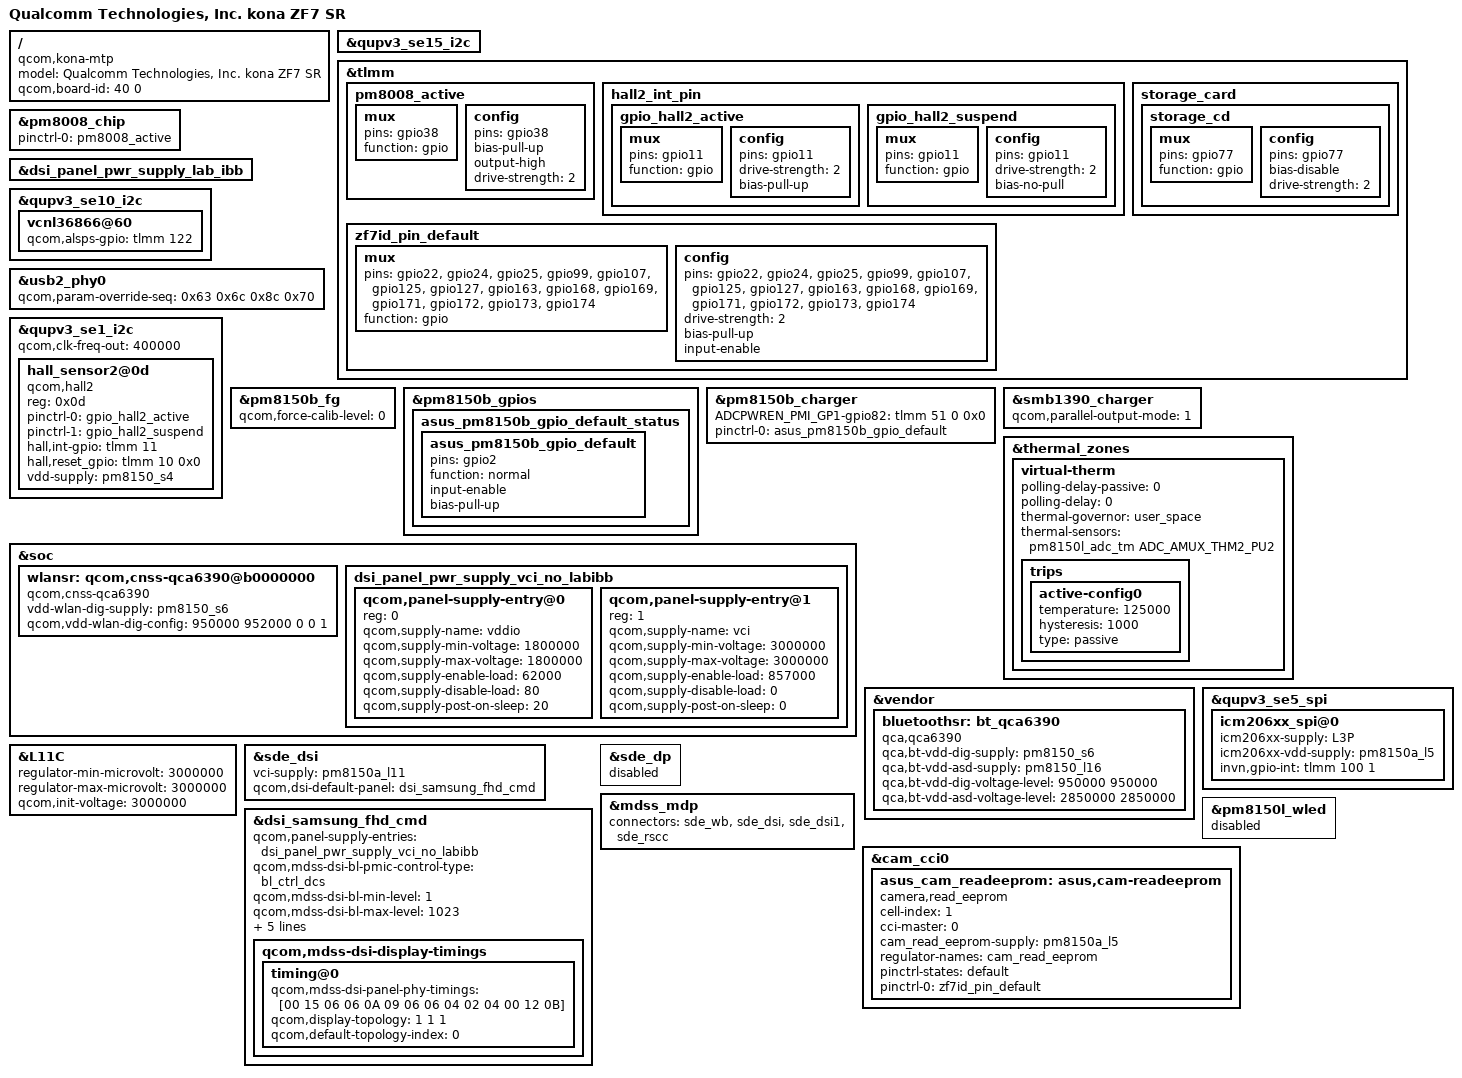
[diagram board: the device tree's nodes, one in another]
/dts-v1/;
/plugin/;

#include "zs670ks-evb-asus-overlay.dts"

#include "dsi-panel-samsung-fhd-cmd.dtsi"
#include "zs670ks-goodix-fp.dtsi"

/* ASUS BSP Clay: PM8008 regulator setting +++ */

&qupv3_se15_i2c {
        status = "ok";
        #include "pm8008.dtsi"
};

&tlmm {
        pm8008_active: pm8008_active {
                mux {
                        pins = "gpio38";
                        function = "gpio";
                };

                config {
                        pins = "gpio38";
                        bias-pull-up;
                        output-high;
                        drive-strength = <2>;
                };
        };
};

&pm8008_chip {
        pinctrl-names = "default";
        pinctrl-0 = <&pm8008_active>;
};


#include "camera/zs670ks-sr-camera-sensor-mtp.dtsi"

/ {
	model = "Qualcomm Technologies, Inc. kona ZF7 SR";
	compatible = "qcom,kona-mtp", "qcom,kona", "qcom,mtp";
	qcom,board-id = <40 0>;
};



/*    ====================================
 *    overlay for kona-v2.dtsi - start
 *    ====================================
 */

/*    ====================================
 *    overlay for kona-v2.dtsi - end
 *    ====================================
 */



/*    ====================================
 *    overlay for kona.dtsi - start
 *    ====================================
 */
&dsi_panel_pwr_supply_lab_ibb{
	/delete-node/ qcom,panel-supply-entry@1;
	/delete-node/ qcom,panel-supply-entry@2; 

};

&qupv3_se10_i2c {
        vcnl36866@60 {
			qcom,alsps-gpio = <&tlmm 122 0x0>;
		};
};

&usb2_phy0 {
	qcom,param-override-seq = < 0x63 0x6c
	                            0x8c 0x70>;
};

//ZS670KS_HALL_sensor_Timo_Xu ++++++++++
&qupv3_se1_i2c {
	status = "ok";
	qcom,clk-freq-out = <400000>;
	hall_sensor2@0d {
		compatible = "qcom,hall2";
		reg=<0x0d>;
		pinctrl-names = "hall2_gpio_high","hall2_gpio_low";
		pinctrl-0 = <&gpio_hall2_active>;
		pinctrl-1 = <&gpio_hall2_suspend>;			
		hall,int-gpio = <&tlmm 11 0x0>;
		hall,reset_gpio= <&tlmm 10 0x0>;
		vdd-supply = <&pm8150_s4>;
	};
};
//ZS670KS_HALL_sensor_Timo_Xu --------

&usb2_phy0 {
	qcom,param-override-seq = < 0x63 0x6c
	                            0x8c 0x70>;
};

 /*    ====================================
 *    overlay for kona.dtsi - end
 *    ====================================
 */


/*    ====================================
 *    overlay for kona-mtp.dtsi - start
 *    ====================================
 */
 
&pm8150b_fg {
		qcom,force-calib-level = <0>;
};
 
 &pm8150b_gpios {
	asus_pm8150b_gpio_default_status {
		asus_pm8150b_gpio_default: asus_pm8150b_gpio_default {
			  pins = "gpio2";
			  function = "normal";
			  input-enable;
			  bias-pull-up;
		  };
	};
};
 
&pm8150b_charger {
	ADCPWREN_PMI_GP1-gpio82 = <&tlmm 51 0 0x0>; //EVB use PM8150B GPIO3, SR use SM8250 GPIO51
	pinctrl-names = "default";
	pinctrl-0 = <&asus_pm8150b_gpio_default>; 
};

&smb1390_charger {
	qcom,parallel-output-mode = <1>;
};

 &thermal_zones { 	
	virtual-therm {
		polling-delay-passive = <0>;
		polling-delay = <0>;
		thermal-governor = "user_space";
		thermal-sensors = <&pm8150l_adc_tm ADC_AMUX_THM2_PU2>;
		trips {
			active-config0 {
				temperature = <125000>;
				hysteresis = <1000>;
				type = "passive";
			};
		};
	};
};

&soc {
	wlansr: qcom,cnss-qca6390@b0000000 {
		compatible = "qcom,cnss-qca6390";
		status = "okay";
		vdd-wlan-dig-supply = <&pm8150_s6>;
		qcom,vdd-wlan-dig-config = <950000 952000 0 0 1>;
	};
};

&vendor {
	bluetoothsr: bt_qca6390 {
		compatible = "qca,qca6390";
		qca,bt-vdd-dig-supply = <&pm8150_s6>;
		qca,bt-vdd-asd-supply = <&pm8150_l16>;
		qca,bt-vdd-dig-voltage-level = <950000 950000>;
		qca,bt-vdd-asd-voltage-level = <2850000 2850000>;
	};

};
/* ASUS_BSP +++ icm20690 */
//remove tmp for ERROR: ufdt_overlay_do_fixups():Couldn't find 'pm8008_l3' symbol in main dtb
&qupv3_se5_spi {
        icm206xx_spi@0 {
                icm206xx-supply = <&L3P>;
                icm206xx-vdd-supply = <&pm8150a_l5>;
                invn,gpio-int = <&tlmm 100 1>;
        };
};
/* ASUS_BSP --- icm20690 */	

&L11C {
	regulator-min-microvolt = <3000000>;
	regulator-max-microvolt = <3000000>;
	qcom,init-voltage = <3000000>;
};

&soc {
	dsi_panel_pwr_supply_vci_no_labibb: dsi_panel_pwr_supply_vci_no_labibb {
		#address-cells = <1>;
		#size-cells = <0>;

		qcom,panel-supply-entry@0 {
			reg = <0>;
			qcom,supply-name = "vddio";
			qcom,supply-min-voltage = <1800000>;
			qcom,supply-max-voltage = <1800000>;
			qcom,supply-enable-load = <62000>;
			qcom,supply-disable-load = <80>;
			qcom,supply-post-on-sleep = <20>;
		};

		qcom,panel-supply-entry@1 {
			reg = <1>;
			qcom,supply-name = "vci";
			qcom,supply-min-voltage = <3000000>;
			qcom,supply-max-voltage = <3000000>;
			qcom,supply-enable-load = <857000>;
			qcom,supply-disable-load = <0>;
			qcom,supply-post-on-sleep = <0>;
		};
	};
};

&sde_dsi {
	vci-supply = <&pm8150a_l11>;
	qcom,dsi-default-panel = <&dsi_samsung_fhd_cmd>;
};

&dsi_samsung_fhd_cmd {
	qcom,panel-supply-entries = <&dsi_panel_pwr_supply_vci_no_labibb>;
	qcom,mdss-dsi-bl-pmic-control-type = "bl_ctrl_dcs";
	qcom,mdss-dsi-bl-min-level = <1>;
	qcom,mdss-dsi-bl-max-level = <1023>;
	qcom,mdss-brightness-max-level = <1023>;
	qcom,mdss-dsi-mode-sel-gpio-state = "single_port";
	qcom,platform-te-gpio = <&tlmm 66 0>;
	qcom,platform-reset-gpio = <&tlmm 75 0>;
	qcom,platform-vddr-enable-gpio = <&tlmm 62 0>;

	qcom,mdss-dsi-display-timings {
		timing@0 {
			qcom,mdss-dsi-panel-phy-timings = [00 15 06 06 0A 09 06
				06 04 02 04 00 12 0B];
			qcom,display-topology = <1 1 1>;
			qcom,default-topology-index = <0>;
		};
	};
};

&sde_dp {
	status = "disabled";
};

&mdss_mdp {
	connectors = <&sde_wb &sde_dsi &sde_dsi1 &sde_rscc>;
};

/*    ====================================
 *    overlay for kona-pinctrl.dtsi - start
 *    ====================================
 */
&tlmm{
		hall2_int_pin {

			gpio_hall2_active: gpio_hall2_active {
 				mux {
 					pins = "gpio11";
 					function = "gpio";
				};
 
 				config {
 					pins = "gpio11";
 					drive-strength = <2>;
 					bias-pull-up;
 				};
 			};
 			gpio_hall2_suspend: gpio_hall2_suspend {
 				mux {
 					pins = "gpio11";
 					function = "gpio";
 				};
 
 				config {
 					pins = "gpio11";
 					drive-strength = <2>;
 					bias-no-pull;
 				};
 			};
		};
};


//Asus bsp change CD gpio status to No-pull as EE request +++
&tlmm{
	storage_card{
		storage_cd: storage_cd {
			mux {
				pins = "gpio77";
				function = "gpio";
			};

			config {
				pins = "gpio77";
				bias-disable;           /*change to No pull*/
				drive-strength = <2>;   /* 2 MA */
			};
		};
	};
};
//Asus bsp change CD gpio status to No-pull as EE request ---

&tlmm{
//Asus bsp Porting ID gpio pull status as EE request +++
	zf7id_pin_default: zf7id_pin_default {
                mux {
                        pins = "gpio22", "gpio24", "gpio25",
							   "gpio99", "gpio107", "gpio125",
							   "gpio127", "gpio163", "gpio168",
							   "gpio169", "gpio171", "gpio172",
							   "gpio173", "gpio174";
						function = "gpio";
                };
                config {
                	pins = "gpio22", "gpio24", "gpio25",
							   "gpio99", "gpio107", "gpio125",
							   "gpio127", "gpio163", "gpio168",
							   "gpio169", "gpio171", "gpio172",
							   "gpio173", "gpio174";
					drive-strength = <2>;   /* 2 mA */
					bias-pull-up;
					input-enable;
                };
        };
//Asus bsp Porting ID gpio pull status as EE request ---	
};

/*    ====================================
 *    overlay for kona-pinctrl.dtsi - end
 *    ====================================
 */



/*    ====================================
 *    overlay for kona-pmic-overlay.dtsi  - start
 *    ====================================
 */

&pm8150l_wled {
	status = "disabled";
};

/*    ====================================
 *    overlay for kona-pmic-overlay.dtsi - end
 *    ====================================
 */



/*    ====================================
 *    overlay for kona-regulator.dtsi - start
 *    ====================================
 */

/*    ====================================
 *    overlay for kona-regulator.dtsi - end
 *    ====================================
 */
 


/*    ====================================
 *    overlay for kona-audio-overlay.dtsi - start
 *    ====================================
 */

/*    ====================================
 *    overlay for kona-audio-overlay.dtsi - end
 *    ====================================
 */





/*    ====================================
 *    overlay for kona-camera-sensor-mtp.dtsi - start
 *    ====================================
 */
 
&cam_cci0 {
	//########### cam_read_eeprom ###########
	asus_cam_readeeprom: asus,cam-readeeprom {
		compatible = "camera,read_eeprom";
		cell-index = <1>;
		cci-master = <0>;
		cam_read_eeprom-supply = <&pm8150a_l5>;    //MCAM0_DOVDD_T_1P8
		regulator-names = "cam_read_eeprom";
		pinctrl-names = "default";
		pinctrl-states = "default";
		pinctrl-0 = <&zf7id_pin_default>; 
		status = "ok";
	};
};
 //Asus bsp Porting ID gpio pull status as EE request, use driver readeeprom as client +++
 /*&asus_cam_readeeprom{
 		pinctrl-names = "default";
		pinctrl-states = "default";
		pinctrl-0 = <&zf7id_pin_default>; 
 };*/
 //Asus bsp Porting ID gpio pull status as EE request, use driver readeeprom as client ---

/*    ====================================
 *    overlay for kona-camera-sensor-mtp.dtsi - end
 *    ====================================
 */
